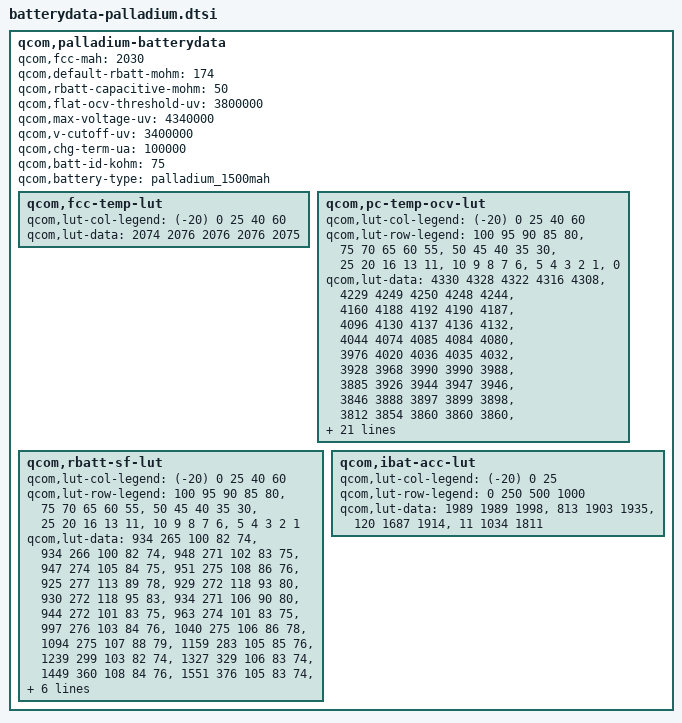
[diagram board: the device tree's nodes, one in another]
/* Copyright (c) 2013-2014, The Linux Foundation. All rights reserved.
 *
 * This program is free software; you can redistribute it and/or modify
 * it under the terms of the GNU General Public License version 2 and
 * only version 2 as published by the Free Software Foundation.
 *
 * This program is distributed in the hope that it will be useful,
 * but WITHOUT ANY WARRANTY; without even the implied warranty of
 * MERCHANTABILITY or FITNESS FOR A PARTICULAR PURPOSE.  See the
 * GNU General Public License for more details.
 */

qcom,palladium-batterydata {
	qcom,fcc-mah = <2030>;
	qcom,default-rbatt-mohm = <174>;
	qcom,rbatt-capacitive-mohm = <50>;
	qcom,flat-ocv-threshold-uv = <3800000>;
	qcom,max-voltage-uv = <4340000>;
	qcom,v-cutoff-uv = <3400000>;
	qcom,chg-term-ua = <100000>;
	qcom,batt-id-kohm = <75>;
	qcom,battery-type = "palladium_1500mah";

	qcom,fcc-temp-lut {
		qcom,lut-col-legend = <(-20) 0 25 40 60>;
		qcom,lut-data = <2074 2076 2076 2076 2075>;
	};

	qcom,pc-temp-ocv-lut {
		qcom,lut-col-legend = <(-20) 0 25 40 60>;
		qcom,lut-row-legend = <100 95 90 85 80>,
				<75 70 65 60 55>,
				<50 45 40 35 30>,
				<25 20 16 13 11>,
				<10 9 8 7 6>,
				<5 4 3 2 1>,
				<0>;
		qcom,lut-data = <4330 4328 4322 4316 4308>,
				<4229 4249 4250 4248 4244>,
				<4160 4188 4192 4190 4187>,
				<4096 4130 4137 4136 4132>,
				<4044 4074 4085 4084 4080>,
				<3976 4020 4036 4035 4032>,
				<3928 3968 3990 3990 3988>,
				<3885 3926 3944 3947 3946>,
				<3846 3888 3897 3899 3898>,
				<3812 3854 3860 3860 3860>,
				<3788 3826 3834 3834 3832>,
				<3770 3800 3812 3812 3810>,
				<3754 3778 3793 3794 3792>,
				<3737 3760 3776 3777 3774>,
				<3720 3744 3760 3758 3750>,
				<3699 3730 3742 3736 3724>,
				<3673 3716 3724 3716 3704>,
				<3646 3705 3706 3698 3684>,
				<3623 3694 3686 3678 3666>,
				<3605 3684 3680 3673 3662>,
				<3592 3679 3678 3671 3660>,
				<3580 3670 3676 3668 3657>,
				<3562 3658 3672 3664 3652>,
				<3544 3642 3663 3656 3640>,
				<3521 3619 3641 3632 3612>,
				<3494 3588 3603 3593 3572>,
				<3462 3549 3552 3542 3524>,
				<3418 3497 3490 3480 3464>,
				<3359 3418 3408 3400 3386>,
				<3260 3297 3284 3276 3268>,
				<3000 3000 3000 3000 3000>;
	};

	qcom,rbatt-sf-lut {
		qcom,lut-col-legend = <(-20) 0 25 40 60>;
		qcom,lut-row-legend = <100 95 90 85 80>,
				<75 70 65 60 55>,
				<50 45 40 35 30>,
				<25 20 16 13 11>,
				<10 9 8 7 6>,
				<5 4 3 2 1>;
		qcom,lut-data = <934 265 100 82 74>,
				<934 266 100 82 74>,
				<948 271 102 83 75>,
				<947 274 105 84 75>,
				<951 275 108 86 76>,
				<925 277 113 89 78>,
				<929 272 118 93 80>,
				<930 272 118 95 83>,
				<934 271 106 90 80>,
				<944 272 101 83 75>,
				<963 274 101 83 75>,
				<997 276 103 84 76>,
				<1040 275 106 86 78>,
				<1094 275 107 88 79>,
				<1159 283 105 85 76>,
				<1239 299 103 82 74>,
				<1327 329 106 83 74>,
				<1449 360 108 84 76>,
				<1551 376 105 83 74>,
				<1455 357 105 83 75>,
				<1589 368 108 85 77>,
				<1755 379 110 86 78>,
				<1960 399 114 89 79>,
				<2246 418 118 90 79>,
				<2603 438 117 87 77>,
				<3099 466 116 88 78>,
				<3795 508 120 90 80>,
				<4806 574 125 94 82>,
				<6469 686 137 101 87>,
				<9769 1016 177 124 101>;
	};

	qcom,ibat-acc-lut {
		qcom,lut-col-legend = <(-20) 0 25>;
		qcom,lut-row-legend = <0 250 500 1000>;
		qcom,lut-data = <1989 1989 1998>,
				<813 1903 1935>,
				<120 1687 1914>,
				<11 1034 1811>;
	};
};
